# nrf7140_wificore register map
Vendor: Nordic Semiconductor; Series: nRF71; File version: 1
Registers are 32-bit, read-write, reset 0x0 unless marked. A register's access mark holds for its fields unless they carry their own. Offsets are from the block's base; [hi:lo] are bit positions; lines under a group give offsets from that group; {n}, {i} and the like mark numbered series; 'fields as' and 'values as' point back to an identical list; <NAME> marks a mode.

## RPUPHY (part 5 of 8) — WIFICore RPU PHY peripherals
Base 0x48080000; alternate view of RPUMAC
0xC000 WLAN_RTM_FD group — Unspecified
  0x00 RESET — WLAN RTM FD RESET
    [2] WLANRTMFDSTATSCOUNTERSRESET — Self-clearing software reset for the statistics counters.
    [1] WLANRTMFDLATCHEDSOFTWARERESET — Latched software reset.
    [0] WLANRTMFDPULSEDSOFTWARERESET — Self-clearing software reset.
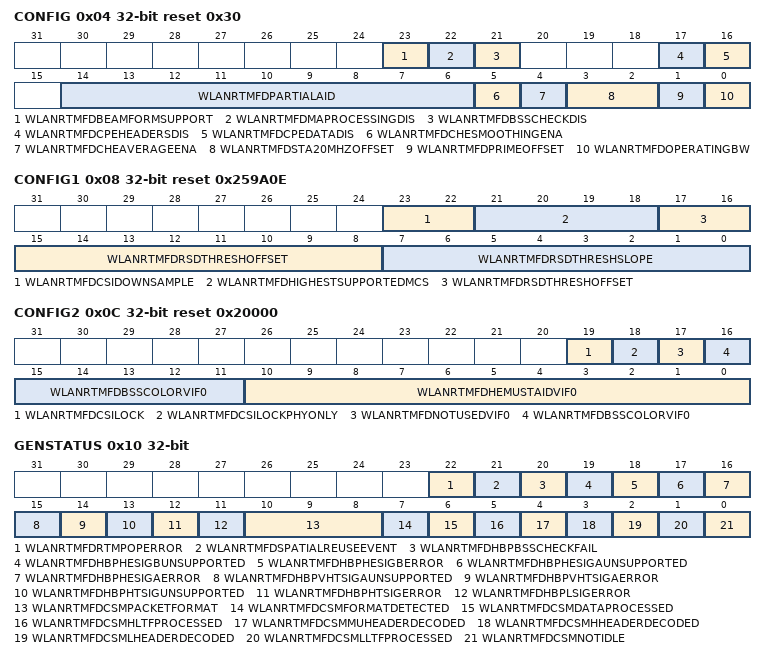
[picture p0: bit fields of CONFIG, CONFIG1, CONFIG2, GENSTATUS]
  0x04 CONFIG reset 0x30 — WLAN RTM FD CONFIG
    [23] WLANRTMFDBEAMFORMSUPPORT — Enable support for Beamforming. When disabled the unsupported flag will be rised when a NDP is detected.
    [22] WLANRTMFDMAPROCESSINGDIS — Disable midambles processing. When disabled the MIMO Channel Estimation matrix is not updated for the midambles.
    [21] WLANRTMFDBSSCHECKDIS — Disable BSS association checks: PARTIAL_AID and BSS_COLOR.
    [17] WLANRTMFDCPEHEADERSDIS — Disable CPE compensation for headers OFDM symbols.
    [16] WLANRTMFDCPEDATADIS — Disable CPE compensation for data OFDM symbols.
    [14:6] WLANRTMFDPARTIALAID — Partial association ID : combination of the association ID and the BSSID.
    [5] WLANRTMFDCHESMOOTHINGENA — Enable / disable channel estimation smoothing.
    [4] WLANRTMFDCHEAVERAGEENA — Enable / disable L-LTF and L-SIG channel estimations average. L-LTF estimation is output when the average is disabled.
    [3:2] WLANRTMFDSTA20MHZOFFSET — Selects the 20MHz partition of the BSS operating bandwidth (up to 80 MHz supported):0-1: when BSS operating bandwidth is 400-3: when BSS operating bandwidth is 80
    [1] WLANRTMFDPRIMEOFFSET — Prime offset for 40 MHz operating bandwidth:
      0=Low; 1=High
    [0] WLANRTMFDOPERATINGBW — Receiver operating bandwidth:
      0=20Mhz; 1=40Mhz
  0x08 CONFIG1 reset 0x259A0E — WLAN RTM FD CONFIG 1
    [23:22] WLANRTMFDCSIDOWNSAMPLE — CSI_DOWNSAMPLE:
      0=NoDownsample; 1=DownsampleBy2; 2=DownsampleBy4
    [21:18] WLANRTMFDHIGHESTSUPPORTEDMCS — Configure the highest supported MCS: detected packets with MCS greater than WLAN_RTM_FD_HIGHEST_SUPPORTED_MCS will be dropped.NOTE: the final highest MCS will be the minimum of this register and the internal value (i.e. HT: 7, VHT: 8 for SigBW20, 9 for SigBW40, HE-SU/MU: 9, HE-ER: 2 for SigBW20, 0 for SigBW40
    [17:8] WLANRTMFDRSDTHRESHOFFSET — Repeated L-SIG detector SNR threshold interpolation offset:threshold =WLAN_RTM_FD_RSD_THRESH_SLOPE * SNRdB + WLAN_RTM_FD_RSD_THRESH_OFFSET
    [7:0] WLANRTMFDRSDTHRESHSLOPE — Repeated L-SIG detector SNR threshold interpolation slope:threshold =WLAN_RTM_FD_RSD_THRESH_SLOPE * SNRdB + WLAN_RTM_FD_RSD_THRESH_OFFSET
  0x0C CONFIG2 reset 0x20000 — WLAN RTM FD CONFIG 2
    [19] WLANRTMFDCSILOCK — CSI lock value, use when WLAN_RTM_FD_CSI_LOCK_PHY_ONLY is set.
    [18] WLANRTMFDCSILOCKPHYONLY — Set when MAC is not present; WLAN_RTM_FD_CSI_LOCK is used.
    [17] WLANRTMFDNOTUSEDVIF0 — Set to mark the VIF0 as not used: STA-ID and BSS color will be ignored.
    [16:11] WLANRTMFDBSSCOLORVIF0 — VIF0 - BSS color of the BSS of which the STA is a member.
    [10:0] WLANRTMFDHEMUSTAIDVIF0 — VIF0 - STA identifier for HE-MU
  0x10 GENSTATUS ro — WLAN RTM FD GEN STATUS
    [22] WLANRTMFDRTMPOPERROR — Indicates POP error event in the RTM-FD.
    [21] WLANRTMFDSPATIALREUSEEVENT — Indicates Spatial Reuse is detected.
    [20] WLANRTMFDHBPBSSCHECKFAIL — Indicates BSS association check failure:- VHT : PARTIAL_AID not matching WLAN_RTM_FD_PARTIAL_AID- HE-SU/HE-ER : BSS_COLOR not matching WLAN_RTM_FD_BSS_COLOR- HE-MU : STA-ID not matching WLAN_RTM_FD_HEMU_STA_ID or not matchig broadcast STA-IDsNote: PARTIAL_AID and BSS_COLOR checks can be disabled by setting WLAN_RTM_FD_BSS_CHECK_DIS register to 1
    [19] WLANRTMFDHBPHESIGBUNSUPPORTED — Indicates HE-SIG-B unsupported feature:- MCS > 9- DCM = 1 if STBC = 1- NSTS > 0 if STBC = 0, NSTS > 1 if STBC = 1
    [18] WLANRTMFDHBPHESIGBERROR — Indicates HE-SIG-B decoding error (common and user fields):- invalid tail bits- CRC check failure
    [17] WLANRTMFDHBPHESIGAUNSUPPORTED — Indicates HE-SIG-A unsupported feature:[HE-SU/HE-ER]- UL detected (PPDU is addressed to an AP)- MCS > 9 if HE-SU, MCS > 2 if HE-ER and Bandwidth = 0, MCS > 0 if HE-ER and Bandwidth = 1- Bandwidth > 1- NSTS > 0 if STBC = 0, NSTS > 1 if STBC = 1- HE-TB detected[HE-MU]- HE-SIGB-MCS > 5, HE-SIGB-MCS = 2 or HE-SIGB-MC > 4 if HE-SIGB-DCM enabled- HE-LTF symbols > 8 if Doppler = 0, HE-LTF symbols > 4 if Doppler = 1
    [16] WLANRTMFDHBPHESIGAERROR — Indicates HE-SIG-A decoding error:- invalid reserved bits- invalid tail bits- CRC check failure- mod(L-SIG[length], 3) == 0
    [15] WLANRTMFDHBPVHTSIGAUNSUPPORTED — Indicates VHT-SIG-A unsupported feature:- Bandwidth > 1- Group ID not 0 or 63 (VHT-MU)- NSTS > 0 if STBC = 0, NSTS > 1 if STBC = 1- MCS > 8 if Bandwidth = 0, MCS > 9 if Bandwidth = 1
    [14] WLANRTMFDHBPVHTSIGAERROR — Indicates VHT-SIG-A decoding error:- invalid reserved bits- invalid tail bits- CRC check failure
    [13] WLANRTMFDHBPHTSIGUNSUPPORTED — Indicates HT-SIG unsupported feature:- MCS > 7- STBC > 1
    [12] WLANRTMFDHBPHTSIGERROR — Indicates HT-SIG decoding error:- invalid reserved bits- invalid tail bits- CRC check failure
    [11] WLANRTMFDHBPLSIGERROR — Indicates L-SIG decoding error:- invalid rate- invalid reserved bits- invalid tail bits- parity check failure
    [10:8] WLANRTMFDCSMPACKETFORMAT — Packet format:
      0=LLegacy; 1=Ht; 2=Reserve (This is reserved.); 3=Vht; 4=HeSu; 5=HeMu; 6=HeEr; 7=HeTb
    [7] WLANRTMFDCSMFORMATDETECTED — Indicates the packet format is detected (valid)
    [6] WLANRTMFDCSMDATAPROCESSED — Indicates all the data OFDM symbols are output to the RXP : L-DATA / HT-DATA / VHT-DATA / HE-DATA
    [5] WLANRTMFDCSMHLTFPROCESSED — Indicates the non-legacy LTF fields processing is completed : HT-LTF / VHT-LTF / HE-LTFestimated channel
    [4] WLANRTMFDCSMMUHEADERDECODED — Indicates the multi-user header is decoded (when it applies) : VHT-SIG-B / HE-SIG-B
    [3] WLANRTMFDCSMHHEADERDECODED — Indicates the non-legacy header is decoded (when it applies) : HT-SIG / VHT-SIG-A / HE-SIG-A
    [2] WLANRTMFDCSMLHEADERDECODED — Indicates the legacy header is decoded : L-SIG
    [1] WLANRTMFDCSMLLTFPROCESSED — Indicates the legacy LTF fields processing is completed : L-LTF estimated channel
    [0] WLANRTMFDCSMNOTIDLE — Indicates the training mode - frequency domain is not idle (i.e. processing packet)
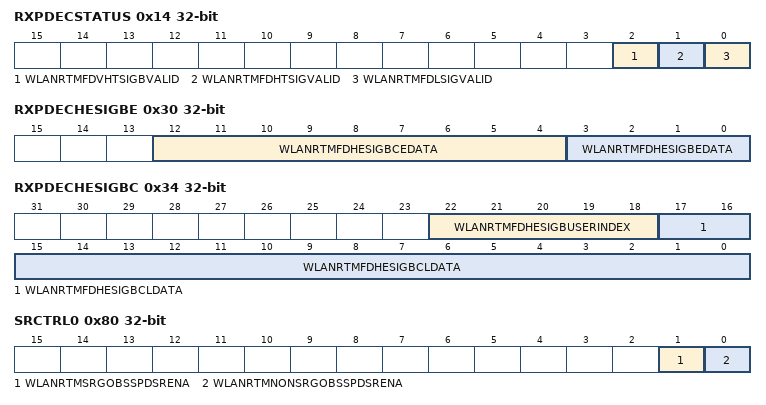
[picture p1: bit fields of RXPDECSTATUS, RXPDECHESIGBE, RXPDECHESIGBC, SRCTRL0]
  0x14 RXPDECSTATUS — WLAN RTM FD RXPDEC STATUS
    [2] WLANRTMFDVHTSIGBVALID — Indicates when the VHT-SIG-B decoded data is available.Note: this register is cleared when soft-reset
    [1] WLANRTMFDHTSIGVALID — Indicates when the HT-SIG / VHT-SIG_A / HE-SIG-A decoded data is available.Note: this register is cleared when soft-reset
    [0] WLANRTMFDLSIGVALID — Indicates when the L-SIG decoded data is available.Note: this register is cleared when soft-reset
  0x18 RXPDECLSIG — WLAN RTM FD RXPDEC LSIG
    [23:0] WLANRTMFDLSIGDATA — L-SIG decoded data - bits 23 .. 0
  0x1C RXPDECHTSIGL — WLAN RTM FD RXPDEC HTSIG L
    [23:0] WLANRTMFDHTSIGLDATA — HT-SIG / VHT-SIG-A / HE-SIG-A1 decoded data - bits 23 .. 0
  0x20 RXPDECHTSIGH — WLAN RTM FD RXPDEC HTSIG H
    [23:0] WLANRTMFDHTSIGHDATA — HT-SIG / VHT-SIG-A / HE-SIG-A decoded data - bits 47 .. 24
  0x24 RXPDECHESIGAE — WLAN RTM FD RXPDEC HESIGA E
    [3:0] WLANRTMFDHESIGAEDATA — HE-SIG-A decoded data - bits 51 .. 48
  0x28 RXPDECVHTSIGBL — WLAN RTM FD RXPDEC VHTSIGB L
    [23:0] WLANRTMFDVHTSIGBLDATA — VHT-SIG-B / HE-SIG-B decoded data - bits 23 .. 0
  0x2C RXPDECVHTSIGBH — WLAN RTM FD RXPDEC VHTSIGB H
    [23:0] WLANRTMFDVHTSIGBHDATA — VHT-SIG-B / HE-SIG-B decoded data - bits 47 .. 24
  0x30 RXPDECHESIGBE — WLAN RTM FD RXPDEC HESIGB E
    [12:4] WLANRTMFDHESIGBCEDATA — HE-SIG-B common field data - bits 26 .. 18
    [3:0] WLANRTMFDHESIGBEDATA — HE-SIG-B decoded data - bits 51 .. 48
  0x34 RXPDECHESIGBC — WLAN RTM FD RXPDEC HESIGB C
    [22:18] WLANRTMFDHESIGBUSERINDEX — HE-SIG-B user field index
    [17:0] WLANRTMFDHESIGBCLDATA — HE-SIG-B common field data - bits 17 .. 0
  0x38 STATSCOUNTER0 — WLAN RTM FD STATS COUNTER 0
    [23:0] WLANRTMOFDMCORRELATIONPASSCOUNT — Number of detected OFDM packets.
  0x3C STATSCOUNTER1 — WLAN RTM FD STATS COUNTER 1
    [23:0] WLANRTMLTFCORRELATIONFAILCOUNT — Number of OFDM packets failed FSB detection - peak not found or peak below the threshold.
  0x40 STATSCOUNTER2 — WLAN RTM FD STATS COUNTER 2
    [23:0] WLANRTMLSIGDECODEFAILCOUNT — Number of OFDM packets failed L-SIG checks - parity or other conditions.
  0x44 STATSCOUNTER3 — WLAN RTM FD STATS COUNTER 3
    [23:0] WLANRTMHTSIGDECODEFAILCOUNT — Number of OFDM packets failed HT-SIG checks - CRC or other conditions.
  0x48 STATSCOUNTER4 — WLAN RTM FD STATS COUNTER 4
    [23:0] WLANRTMVHTSIGADECODEFAILCOUNT — Number of OFDM packets failed VHT-SIG-A checks - CRC or other conditions.
  0x4C STATSCOUNTER5 — WLAN RTM FD STATS COUNTER 5
    [23:0] WLANRTMHESIGADECODEFAILCOUNT — Number of OFDM packets failed HE-SIG-A checks - CRC or other conditions.
  0x50 STATSCOUNTER6 — WLAN RTM FD STATS COUNTER 6
    [23:0] WLANRTMHESIGBDECODEFAILCOUNT — Number of OFDM packets failed HE-SIG-B checks - CRC or other conditions.
  0x54 FRAMECOUNTER0 — WLAN RTM FD FRAME COUNTER 0
    [23:0] WLANRTMLEGACYFRAMECOUNT — Number of Legacy frames received - increments when the last DATA symbol is sent to the RXP.
  0x58 FRAMECOUNTER1 — WLAN RTM FD FRAME COUNTER 1
    [23:0] WLANRTMHTFRAMECOUNT — Number of HT frames received - increments when the last DATA symbol is sent to the RXP.
  0x5C FRAMECOUNTER2 — WLAN RTM FD FRAME COUNTER 2
    [23:0] WLANRTMVHTFRAMECOUNT — Number of VHT frames received - increments when the last DATA symbol is sent to the RXP.
  0x60 FRAMECOUNTER3 — WLAN RTM FD FRAME COUNTER 3
    [23:0] WLANRTMHESUFRAMECOUNT — Number of HE-SU frames received - increments when the last DATA symbol is sent to the RXP.
  0x64 FRAMECOUNTER4 — WLAN RTM FD FRAME COUNTER 4
    [23:0] WLANRTMHEERFRAMECOUNT — Number of HE-ER-SU frames received - increments when the last DATA symbol is sent to the RXP.
  0x68 FRAMECOUNTER5 — WLAN RTM FD FRAME COUNTER 5
    [23:0] WLANRTMHEMUFRAMECOUNT — Number of HE-MU frames received - increments when the last DATA symbol is sent to the RXP.
  0x6C FRAMECOUNTER6 — WLAN RTM FD FRAME COUNTER 6
    [23:0] WLANRTMUNSUPPORTEDFRAMECOUNT — Number of received OFDM packets with unsupporterd features - increments when fields of HT-SIG / VHT-SIG-A /HE-SIG-A / HE-SIG-B indicate capabilities/features that are not supported by STA and header is succesfully decoded.
  0x70 FRAMECOUNTER7 — WLAN RTM FD FRAME COUNTER 7
    [23:0] WLANRTMOTHERSTAFRAMECOUNT — Number of received OFDM packets where packet ID not matcing the STA ID - increments when Partial AID (VHT), BSS Color (HE-SU/HE-ER-SU) or User Field (HE-MU) not matching the configured value and header is succesfully decoded.
  0x74 FRAMECOUNTER8 — WLAN RTM FD FRAME COUNTER 8
    [23:0] WLANRTMVHTNDPFRAMECOUNT — Number of VHT NDP frames received - increments when the last VHT-LTF symbol is sent to the SVD.
  0x78 FRAMECOUNTER9 — WLAN RTM FD FRAME COUNTER 9
    [23:0] WLANRTMHESUNDPFRAMECOUNT — Number of HE-SU NDP frames received - increments when the last HE-LTF symbol is sent to the SVD.
  0x7C STATSCOUNTER7 — WLAN RTM FD STATS COUNTER 7
    [23:0] WLANRTMS2LTIMEOUTFAILCOUNT — Number of OFDM packets failed due to missing S2L event.
  0x80 SRCTRL0 — WLAN RTM FD SR CTRL 0
    [1] WLANRTMSRGOBSSPDSRENA — Enable spatial reuse in overlapping-BSS with preamble detection in spatial reuse group cases.
    [0] WLANRTMNONSRGOBSSPDSRENA — Enable spatial reuse in overlapping-BSS with preamble detection in non-spatial reuse group cases.
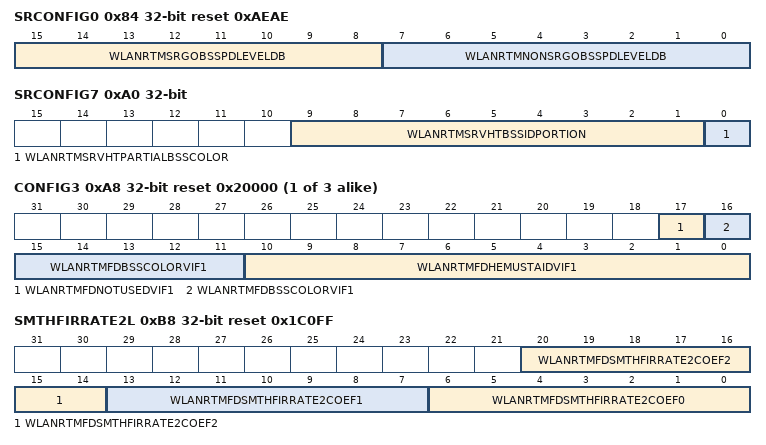
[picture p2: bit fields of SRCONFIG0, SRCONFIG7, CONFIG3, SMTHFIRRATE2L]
  0x84 SRCONFIG0 reset 0xAEAE — WLAN RTM FD SR CONFIG 0
    [15:8] WLANRTMSRGOBSSPDLEVELDB — Preamble detection level in dBm for spatial reuse group cases (s7.0). Valid Range : -82 to -62 dBm
    [7:0] WLANRTMNONSRGOBSSPDLEVELDB — Preamble detection level in dBm for non spatial reuse group cases (s7.0). Valid Range : -82 to -62 dBm
  0x88 SRCONFIG1 — WLAN RTM FD SR CONFIG 1
    [23:0] WLANRTMSRGPARTIALBSSIDBITMAP0 — Indicates the Partial BSSID values used by members of the SRG of which the transmitting STA is a member - bits 23 downto 0. Note: Each bit of the bitmap corresponds to one of the 64 possible values of BSSID[39:44], where the lowest numbered bit corresponds to Partial BSSID value 0 and the highest numbered bit corresponds to Partial BSSID value 63
  0x8C SRCONFIG2 — WLAN RTM FD SR CONFIG 2
    [23:0] WLANRTMSRGPARTIALBSSIDBITMAP1 — Indicates the Partial BSSID values used by members of the SRG of which the transmitting STA is a member - bits 47 downto 24. Note: Each bit of the bitmap corresponds to one of the 64 possible values of BSSID[39:44], where the lowest numbered bit corresponds to Partial BSSID value 0 and the highest numbered bit corresponds to Partial BSSID value 63
  0x90 SRCONFIG3 — WLAN RTM FD SR CONFIG 3
    [15:0] WLANRTMSRGPARTIALBSSIDBITMAP2 — Indicates the Partial BSSID values used by members of the SRG of which the transmitting STA is a member - bits 63 downto 48. Note: Each bit of the bitmap corresponds to one of the 64 possible values of BSSID[39:44], where the lowest numbered bit corresponds to Partial BSSID value 0 and the highest numbered bit corresponds to Partial BSSID value 63
  0x94 SRCONFIG4 — WLAN RTM FD SR CONFIG 4
    [23:0] WLANRTMSRGBSSCOLORBITMAP0 — Indicates the BSS color values used by members of the SRG of which the transmitting STA is a member - bits 23 downto 0. Note: Each bit of the bitmap corresponds to one of the 64 BSS colors, where the lowest numbered bit corresponds to BSS color value 0 and the highest numbered bit corresponds to BSS color value 63.The bit in the bitmap that corresponds to the BSS color value 0 is reserved
  0x98 SRCONFIG5 — WLAN RTM FD SR CONFIG 5
    [23:0] WLANRTMSRGBSSCOLORBITMAP1 — Indicates the BSS color values used by members of the SRG of which the transmitting STA is a member - bits 47 downto 24. Note: Each bit of the bitmap corresponds to one of the 64 BSS colors, where the lowest numbered bit corresponds to BSS color value 0 and the highest numbered bit corresponds to BSS color value 63.The bit in the bitmap that corresponds to the BSS color value 0 is reserved
  0x9C SRCONFIG6 — WLAN RTM FD SR CONFIG 6
    [15:0] WLANRTMSRGBSSCOLORBITMAP2 — Indicates the BSS color values used by members of the SRG of which the transmitting STA is a member - bits 63 downto 48. Note: Each bit of the bitmap corresponds to one of the 64 BSS colors, where the lowest numbered bit corresponds to BSS color value 0 and the highest numbered bit corresponds to BSS color value 63.The bit in the bitmap that corresponds to the BSS color value 0 is reserved
  0xA0 SRCONFIG7 — WLAN RTM FD SR CONFIG 7
    [9:1] WLANRTMSRVHTBSSIDPORTION — VHT specific BSSID portion
    [0] WLANRTMSRVHTPARTIALBSSCOLOR — Partial BSS color field/
  0xA4 STATSCOUNTER8 — WLAN RTM FD STATS COUNTER 8
    [23:0] WLANRTMSPATIALREUSEEVENTCOUNT — Number of Spatial Reuse events detected.
  {0x9C+4j} CONFIG{j} reset 0x20000 (j=3..5) — WLAN RTM FD CONFIG {j}
    [17] WLANRTMFDNOTUSEDVIF{j-2} — Set to mark the VIF{j-2} as not used: STA-ID and BSS color will be ignored.
    [16:11] WLANRTMFDBSSCOLORVIF{j-2} — VIF{j-2} - BSS color of the BSS of which the STA is a member.
    [10:0] WLANRTMFDHEMUSTAIDVIF{j-2} — VIF{j-2} - STA identifier for HE-MU
  0xB4 CONFIG6 — WLAN RTM FD CONFIG 6
    [10:0] WLANRTMFDHEMUBSSIDINDEX — BSSID index field for a non-transmitted BSSID; set to 0 for transmitted BSSID
  0xB8 SMTHFIRRATE2L reset 0x1C0FF — WLAN RTM FD SMTH FIR RATE2 L
    [20:14] WLANRTMFDSMTHFIRRATE2COEF2 — Smoothing FIR filter, Tu/GI rate 2, coefficient 2, s0.6, default 7
    [13:7] WLANRTMFDSMTHFIRRATE2COEF1 — Smoothing FIR filter, Tu/GI rate 2, coefficient 1, s0.6, default 1
    [6:0] WLANRTMFDSMTHFIRRATE2COEF0 — Smoothing FIR filter, Tu/GI rate 2, coefficient 0, s0.6, default -1
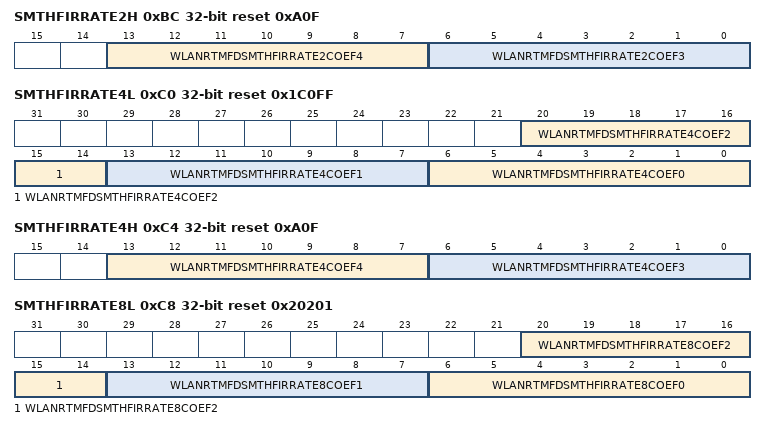
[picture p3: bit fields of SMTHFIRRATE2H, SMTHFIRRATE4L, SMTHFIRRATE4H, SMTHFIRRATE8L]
  0xBC SMTHFIRRATE2H reset 0xA0F — WLAN RTM FD SMTH FIR RATE2 H
    [13:7] WLANRTMFDSMTHFIRRATE2COEF4 — Smoothing FIR filter, Tu/GI rate 2, coefficient 4, s0.6, default 20
    [6:0] WLANRTMFDSMTHFIRRATE2COEF3 — Smoothing FIR filter, Tu/GI rate 2, coefficient 3, s0.6, default 15
  0xC0 SMTHFIRRATE4L reset 0x1C0FF — WLAN RTM FD SMTH FIR RATE4 L
    [20:14] WLANRTMFDSMTHFIRRATE4COEF2 — Smoothing FIR filter, Tu/GI rate 4, coefficient 2, s0.6, default 7
    [13:7] WLANRTMFDSMTHFIRRATE4COEF1 — Smoothing FIR filter, Tu/GI rate 4, coefficient 1, s0.6, default 1
    [6:0] WLANRTMFDSMTHFIRRATE4COEF0 — Smoothing FIR filter, Tu/GI rate 4, coefficient 0, s0.6, default -1
  0xC4 SMTHFIRRATE4H reset 0xA0F — WLAN RTM FD SMTH FIR RATE4 H
    [13:7] WLANRTMFDSMTHFIRRATE4COEF4 — Smoothing FIR filter, Tu/GI rate 4, coefficient 4, s0.6, default 20
    [6:0] WLANRTMFDSMTHFIRRATE4COEF3 — Smoothing FIR filter, Tu/GI rate 4, coefficient 3, s0.6, default 15
  0xC8 SMTHFIRRATE8L reset 0x20201 — WLAN RTM FD SMTH FIR RATE8 L
    [20:14] WLANRTMFDSMTHFIRRATE8COEF2 — Smoothing FIR filter, Tu/GI rate 8, coefficient 2, s0.6, default 8
    [13:7] WLANRTMFDSMTHFIRRATE8COEF1 — Smoothing FIR filter, Tu/GI rate 8, coefficient 1, s0.6, default 4
    [6:0] WLANRTMFDSMTHFIRRATE8COEF0 — Smoothing FIR filter, Tu/GI rate 8, coefficient 0, s0.6, default 1
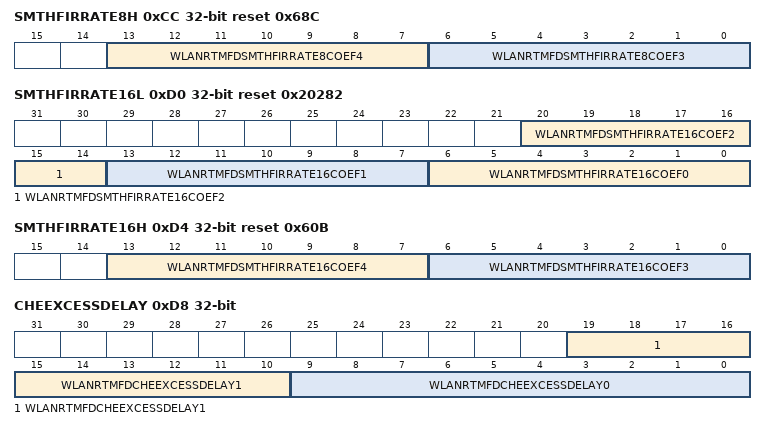
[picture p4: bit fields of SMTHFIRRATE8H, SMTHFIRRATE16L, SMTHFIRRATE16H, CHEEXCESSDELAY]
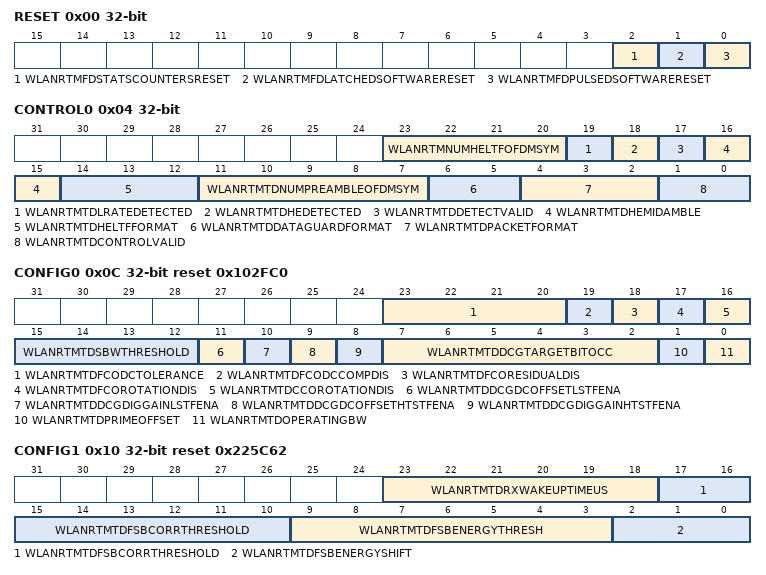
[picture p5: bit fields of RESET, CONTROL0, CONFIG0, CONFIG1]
  0xCC SMTHFIRRATE8H reset 0x68C — WLAN RTM FD SMTH FIR RATE8 H
    [13:7] WLANRTMFDSMTHFIRRATE8COEF4 — Smoothing FIR filter, Tu/GI rate 8, coefficient 4, s0.6, default 13
    [6:0] WLANRTMFDSMTHFIRRATE8COEF3 — Smoothing FIR filter, Tu/GI rate 8, coefficient 3, s0.6, default 12
  0xD0 SMTHFIRRATE16L reset 0x20282 — WLAN RTM FD SMTH FIR RATE16 L
    [20:14] WLANRTMFDSMTHFIRRATE16COEF2 — Smoothing FIR filter, Tu/GI rate 16, coefficient 2, s0.6, default 8
    [13:7] WLANRTMFDSMTHFIRRATE16COEF1 — Smoothing FIR filter, Tu/GI rate 16, coefficient 1, s0.6, default 5
    [6:0] WLANRTMFDSMTHFIRRATE16COEF0 — Smoothing FIR filter, Tu/GI rate 16, coefficient 0, s0.6, default 2
  0xD4 SMTHFIRRATE16H reset 0x60B — WLAN RTM FD SMTH FIR RATE16 H
    [13:7] WLANRTMFDSMTHFIRRATE16COEF4 — Smoothing FIR filter, Tu/GI rate 16, coefficient 4, s0.6, default 12
    [6:0] WLANRTMFDSMTHFIRRATE16COEF3 — Smoothing FIR filter, Tu/GI rate 16, coefficient 3, s0.6, default 11
  0xD8 CHEEXCESSDELAY ro — WLAN RTM FD CHE EXCESS DELAY
    [19:10] WLANRTMFDCHEEXCESSDELAY1 — Excess Delay estimate at channel smoothing for the second stream, s0.9
    [9:0] WLANRTMFDCHEEXCESSDELAY0 — Excess Delay estimate at channel smoothing for the first stream, s0.9
  0xDC CHEDMALENGTH — WLAN RTM FD CHE DMA LENGTH
    [8:0] WLANRTMFDCHEDMALENGTH — Transfer specified number of channel estimates to the EDC through the channel estimates TBus read port. Register value decrements as the channel estimates are transferred.
0xD000 WLAN_RTM_TD group — Unspecified
  0x00 RESET — WLAN RTM TD RESET
    [2] WLANRTMTDSTATSCOUNTERSRESET — Self-clearing software reset for the statistics counters.
    [1] WLANRTMTDLATCHEDSOFTWARERESET — Latched software reset.
    [0] WLANRTMTDPULSEDSOFTWARERESET — Self-clearing software reset.
  0x04 CONTROL0 — WLAN RTM TD CONTROL 0
    [23:20] WLANRTMNUMHELTFOFDMSYM — Number of HE-LTF OFDM symbols in the preamble section (do NOT include the midables HE-LTFs)Note: default value set when software reset
    [19] WLANRTMTDLRATEDETECTED — L-SIG 6 Mbps detection flag :Note: default value set when software reset
      0=LSigRateNot6Mbps; 1=LSigRateIs6Mbps
    [18] WLANRTMTDHEDETECTED — HE detection flag :Note: default value set when software reset
      0=NonHeDetected; 1=HeDetected
    [17] WLANRTMTDDETECTVALID — Indicates the detection control register fields are valid.Note: default value set when software reset
      0=Detection control register fields not yet set; 1=WLAN_RTM_TD_HE_DETECTED and WLAN_RTM_TD_LRATE_DETECTED are valid
    [16:15] WLANRTMTDHEMIDAMBLE — HE-LTF format :Note: default value set when software reset
      0=NoMidambles; 1=Reserve (This is reserved.); 2=Midambles every 10 OFDM data symbols,; 3=Midambles every 20 OFDM data symbols
    [14:12] WLANRTMTDHELTFFORMAT — HE-LTF format :0: 1x HE-LTF (3.2us)+ 0.8us GI,1: 1x HE-LTF (3.2us)+ 1.6us GI,2: 2x HE-LTF (6.4us)+ 0.8us GI,3: 2x HE-LTF (6.4us)+ 1.6us GI,4: 4x HE-LTF (12.8us) + 0.8us GI,5: 4x HE-LTF (12.8us) + 3.2us GI,6-7: ReservedNote: default value set when software reset
    [11:7] WLANRTMTDNUMPREAMBLEOFDMSYM — Number of preamble / header OFDM symbols, counting after L-SIG (i.e. for legacy packet the value is zero)Note: default value set when software reset
    [6:5] WLANRTMTDDATAGUARDFORMAT — Guard duration for DATA symbols :
      0=04UsLegacyShort; 1=08UsLegacyLong; 2=16Us; 3=32Us
    [4:2] WLANRTMTDPACKETFORMAT — Packet format:Note: default value set when software reset
      values as WLAN_RTM_FD.GENSTATUS.WLANRTMFDCSMPACKETFORMAT
    [1:0] WLANRTMTDCONTROLVALID — Indicates the control registers WLAN_RTM_TD_CONTROL_0 and WLAN_RTM_TD_CONTROL_1 are valid.Note: default value set when software reset
      0=Control registers not yet set; 1=Only WLAN_RTM_TD_PACKET_FORMAT is valid; 2=Legacy fields decoding control registers are valid; 3=All the control registers are valid
  0x08 CONTROL1 — WLAN RTM TD CONTROL 1
    [23:0] WLANRTMTDNUMDATAOFDMSYM — Number of data and midamble (HE only) OFDM symbols. Considered valid if WLAN_RTM_TD_CONTROL_VALID is 2 or 3.Note: default value set when software reset
  0x0C CONFIG0 reset 0x102FC0 — WLAN RTM TD CONFIG 0
    [23:20] WLANRTMTDFCODCTOLERANCE — ?? Tolerance for the FCO-DC estimation calculation (u-8.12).
    [19] WLANRTMTDFCODCCOMPDIS — Disable / enable fine DC offset compensation in FCO.
    [18] WLANRTMTDFCORESIDUALDIS — Disable / enable residual frequency offset correction.
    [17] WLANRTMTDFCOROTATIONDIS — Disable / enable fine carrier frequency offset correction.
    [16] WLANRTMTDCCOROTATIONDIS — Disable / enable coarse carrier frequency offset correction.
    [15:12] WLANRTMTDSBWTHRESHOLD — Signal bandwidth detection threshold (u4.0).
    [11] WLANRTMTDDCGDCOFFSETLSTFENA — Enable / disable DC offset compensation for L-STF.
    [10] WLANRTMTDDCGDIGGAINLSTFENA — Enable / disable digital gain compensation for L-STF.
    [9] WLANRTMTDDCGDCOFFSETHTSTFENA — Enable / disable DC offset compensation for HT-STF/VHT-STF/HE-STF (2nd AGC enabled).
    [8] WLANRTMTDDCGDIGGAINHTSTFENA — Enable / disable digital gain compensation for HT-STF/VHT-STF/HE-STF (2nd AGC enabled).
    [7:2] WLANRTMTDDCGTARGETBITOCC — Digital gain target bit occupancy in dB (u6.0).Default value corresponds to 12 bits SCP (full scale) and 18 dB headroom.
    [1] WLANRTMTDPRIMEOFFSET — Prime offset for 40 MHz operating bandwidth:
      0=Low; 1=High
    [0] WLANRTMTDOPERATINGBW — Receiver operating bandwidth:
      0=20Mhz; 1=40Mhz
  0x10 CONFIG1 reset 0x225C62 — WLAN RTM TD CONFIG 1
    [23:18] WLANRTMTDRXWAKEUPTIMEUS — Standby to Active time in us (u4.2).Note: Used to enable RX prior to expiry of the packet duration counter when Power Save mode is active.
    [17:10] WLANRTMTDFSBCORRTHRESHOLD — Fine symbol boundary energy correlation threshold ratio (u0.8).
    [9:3] WLANRTMTDFSBENERGYTHRESH — Fine symbol boundary peak detection threshold ratio (u0.7).
    [2:0] WLANRTMTDFSBENERGYSHIFT — Fine symbol boundary energy scale shift (u3.0).
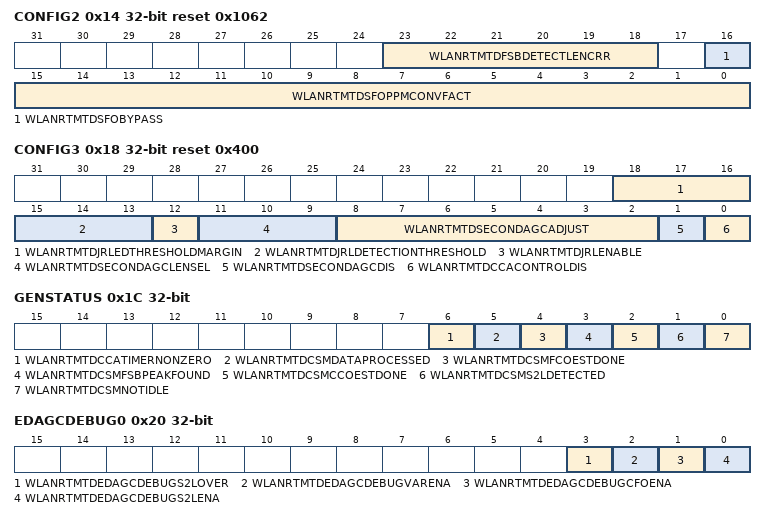
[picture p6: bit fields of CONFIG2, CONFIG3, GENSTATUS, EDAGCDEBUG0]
  0x14 CONFIG2 reset 0x1062 — WLAN RTM TD CONFIG 2
    [23:18] WLANRTMTDFSBDETECTLENCRR — Fine symbol boundary detection length correction factor (s5.0).
    [16] WLANRTMTDSFOBYPASS — Bypass Sample Frequency Offset when set to 1
    [15:0] WLANRTMTDSFOPPMCONVFACT — Sampling Frequency Offset, time tracking conversion factor: value of [resampler factor] * OpBW/fc,where OpBw is the operating bandwidth and fc is the channel centre frequency. (u-4.20)Note: default value set for resampler factor = 1, OpBW = 20MHz and fc = 5GHz
  0x18 CONFIG3 reset 0x400 — WLAN RTM TD CONFIG 3
    [18:16] WLANRTMTDJRLEDTHRESHOLDMARGIN — Headroom added to the minimum variance for OFDM correlation once Jammer signal is detected in dB (u3.0).
    [15:13] WLANRTMTDJRLDETECTIONTHRESHOLD — Jammer Detection Threshold. Total number of s2lFails required to trigger Jammer detection - 1 (u3.0).
    [12] WLANRTMTDJRLENABLE — Enable/disable Jammer Rejection Logic : ED threshold and minimum variance for OFDM correlation PASS increased toED RSSI snapshot + EdThresholdMargin when Jammer is detected.
    [11:9] WLANRTMTDSECONDAGCLENSEL — Second AGC estimation window length selection: ceil(log2(0.8*Fs)) - 3, where Fs is the ADC sampling rate.Note: default value is set assuming Fs equals 40MHz
    [8:2] WLANRTMTDSECONDAGCADJUST — Second AGC start wait time adjustment in number of samples. (s6.0)
    [1] WLANRTMTDSECONDAGCDIS — Disable / enable AGC control for the second estimation (ED/AGC).
    [0] WLANRTMTDCCACONTROLDIS — Disable / enable CCA control for correlation indication and status known (ED).Timer non-zero flag always zero when disabled.
  0x1C GENSTATUS ro — WLAN RTM TD GEN STATUS
    [6] WLANRTMTDCCATIMERNONZERO — CCA timer non-zero
    [5] WLANRTMTDCSMDATAPROCESSED — Indicates all the OFDM symbols are output to the FFT
    [4] WLANRTMTDCSMFCOESTDONE — Indicates the fine frequency offset is estimated
    [3] WLANRTMTDCSMFSBPEAKFOUND — Indicates the FSB index is calculated : LTF correlation
    [2] WLANRTMTDCSMCCOESTDONE — Indicates the coarse frequency offset is estimated
    [1] WLANRTMTDCSMS2LDETECTED — Indicates the S2L event is asserted by the ED
    [0] WLANRTMTDCSMNOTIDLE — Indicates the training mode - time domain is not idle (i.e. processing packet)
  0x20 EDAGCDEBUG0 — WLAN RTM TD EDAGC DEBUG 0
    [3] WLANRTMTDEDAGCDEBUGS2LOVER — S2LOver flag emulation : overwrites input signal cin_s2l_over_event.
    [2] WLANRTMTDEDAGCDEBUGVARENA — Enable/disable ED-AGC debug support : ED-AGC prime variance signals from registers WLAN_RTM_TD_EDAGC_PRIME20_VAR/WLAN_RTM_TD_EDAGC_PRIME40_VAR.
    [1] WLANRTMTDEDAGCDEBUGCFOENA — Enable/disable ED-AGC debug support : ED-AGC CFO signals from registers WLAN_RTM_TD_EDAGC_CFO_RE/WLAN_RTM_TD_EDAGC_CFO_IM.
    [0] WLANRTMTDEDAGCDEBUGS2LENA — Enable/disable ED-AGC debug support : ED-AGC S2L-over signal from register WLAN_RTM_TD_EDAGC_DEBUG_S2LOVER.
  0x24 EDAGCDEBUG1 — WLAN RTM TD EDAGC DEBUG 1
    [23:0] WLANRTMTDEDAGCCFORE — ED CFO emulation : overwrites input signal cin_edagccfo_re (s0.23).
  0x28 EDAGCDEBUG2 — WLAN RTM TD EDAGC DEBUG 2
    [23:0] WLANRTMTDEDAGCCFOIM — ED CFO emulation : overwrites input signal cin_edagccfo_im (s0.23).
  0x2C EDAGCDEBUG3 — WLAN RTM TD EDAGC DEBUG 3
    [19:0] WLANRTMTDEDAGCPRIME20VAR — ED Prime20 variance emulation : overwrites input signal cin_edprime20_var (u20.0).
  0x30 EDAGCDEBUG4 — WLAN RTM TD EDAGC DEBUG 4
    [19:0] WLANRTMTDEDAGCPRIME40VAR — ED Prime20 variance emulation : overwrites input signal cin_edprime40_var (u20.0).
  0x34 DCGSTATUS0 ro — WLAN RTM TD DCG STATUS 0
    [23:0] WLANRTMTDDCGDCOFFSETLSTF — DC offset estimation for L-STF - complex (s-1.12).
  0x38 DCGSTATUS1 ro — WLAN RTM TD DCG STATUS 1
    [8:0] WLANRTMTDDCGDIGITALGAINLSTFDB — Digital gain estimation for L-STF in dBs (s6.2).
  0x3C DCGSTATUS2 ro — WLAN RTM TD DCG STATUS 2
    [23:0] WLANRTMTDDCGDCOFFSETHTSTF — DC offset estimation for HT-STF/VHT-STF/HE-STF - complex (s-1.12).
  0x40 DCGSTATUS3 ro — WLAN RTM TD DCG STATUS 3
    [8:0] WLANRTMTDDCGDIGITALGAINHTSTFDB — Digital gain estimation for HT-STF/VHT-STF/HE-STF in dBs (s6.2).
  0x44 CFOSTATUS0 ro — WLAN RTM TD CFO STATUS 0
    [15:0] WLANRTMTDCCOFREQUENCYOFFSET — Coarse frequency offset estimation (s-5.20).
  0x48 CFOSTATUS1 ro — WLAN RTM TD CFO STATUS 1
    [15:0] WLANRTMTDFCOFREQUENCYOFFSET — Fine frequency offset estimation (s-5.20).
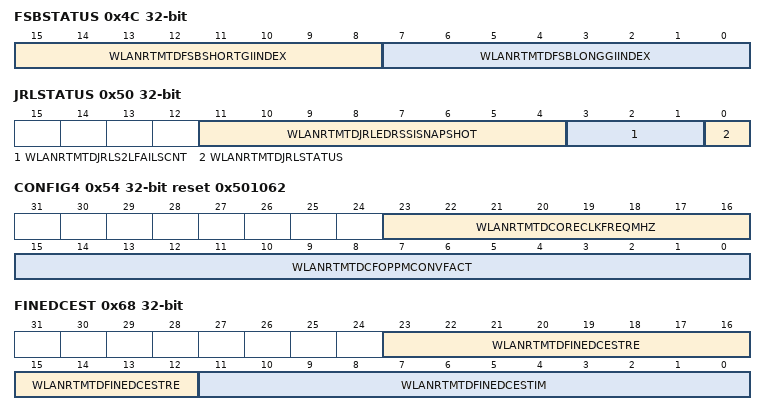
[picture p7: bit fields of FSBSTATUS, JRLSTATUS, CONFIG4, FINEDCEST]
  0x4C FSBSTATUS ro — WLAN RTM TD FSB STATUS
    [15:8] WLANRTMTDFSBSHORTGIINDEX — FSB index for the short guard interval (s7.0).
    [7:0] WLANRTMTDFSBLONGGIINDEX — FSB index for the long guard interval (s7.0).
  0x50 JRLSTATUS ro — WLAN RTM TD JRL STATUS
    [11:4] WLANRTMTDJRLEDRSSISNAPSHOT — ED RSSI (in dBm) snapshot taken after the latest ED-done event.
    [3:1] WLANRTMTDJRLS2LFAILSCNT — Consecutive number of S2L fails after every ED.
    [0] WLANRTMTDJRLSTATUS — Jammer detection status (cleared on low energy detection):
      0=no Jammer has been detected; 1=Jammer has been detected (number of consecutive S2L fails equals JRL_DETECTION_THRESHOLD)
  0x54 CONFIG4 reset 0x501062 — WLAN RTM TD CONFIG 4
    [23:16] WLANRTMTDCORECLKFREQMHZ — Core clock frequency in MHz. (u8.0)
    [15:0] WLANRTMTDCFOPPMCONVFACT — Carrier Frequency Offset, to PPM conversion factor: value of OpBW/fc,where OpBw is the operating bandwidth and fc is the channel centre frequency. (u-4.20)Note: default value set for OpBW = 20MHz and fc = 5GHz
  0x58 STATSCOUNTER0 — WLAN RTM TD STATS COUNTER 0
    [23:0] WLANRTMLOWENERGYEVENTCOUNT — Number of low energy events detected.
  0x5C STATSCOUNTER1 — WLAN RTM TD STATS COUNTER 1
    [23:0] WLANRTMPOPEVENTCOUNT — Number of packet-over-packet events detected.
  0x60 CONFIG5 reset 0x1D — WLAN RTM TD CONFIG 5
    [7:0] WLANRTMRSSICONVFACTOR — The LTF-RSSI conversion factor. s7.0This factor represents the conversion from voltage domain (power in dBm) in analog to digital representation of IQ's.LTF_RSSI_DBM = LTF_POWER_DB - AGC_GAIN_DB - DGC_GAIN_DB - WLAN_RTM_RSSI_CONV_FACTOR
  0x64 RSSISTATUS ro — WLAN RTM TD RSSI STATUS
    [7:0] WLANRTMTDRSSILTFDBM — The RSSI computation of HT-LTF/VHT-LTF/HE-LTF is an indicative of the DATA field power in dBm.
  0x68 FINEDCEST ro — WLAN RTM TD FINE DC EST
    [23:12] WLANRTMTDFINEDCESTRE — Fine DC estimation real part S-1.12.
    [11:0] WLANRTMTDFINEDCESTIM — Fine DC estimation imaginary part S-1.12.
  0x6C STATSCOUNTER2 — WLAN RTM TD STATS COUNTER 2
    [23:0] WLANRTMMIDPACKETDETECTCOUNT — Number of mid-packet detected.
  0x70 DEBUGGING — WLAN RTM TD DEBUG
    [1:0] WLANRTMTDDEBUG — Enable debug registers WLAN_RTM_TD_DEBUG_VALID and WLAN_RTM_TD_DEBUG_ENABLE
      0=Disabled; 1=ValidEnable; 2=Sticky(Valid), Sticky(Enable); 3=Valid & Enable, Sticky(Valid & Enable)
  0x74 DEBUGVALID ro — WLAN RTM TD DEBUG VALID
    [19:0] WLANRTMTDDEBUGVALID — Live state of the valid flow control signals0: valid_up_l1: valid_dw_l2: dcg_valid_up3: dcg_fco_valid_up4: dcg_valid_dw5: atn_valid_up6: atn_valid_dw7: cco_valid_up8: cco_valid_dw9: cco_atn_valid10: atn_cco_valid11: fsb_valid_up12: fsb_valid_dw13: fco_valid_up14: fco_valid_dw15: fco_atn_valid16: atn_fco_valid17: rsd_atn_valid18: sbw_valid_up19: sbw_valid_dw
  0x78 DEBUGENABLE ro — WLAN RTM TD DEBUG ENABLE
    [19:0] WLANRTMTDDEBUGENABLE — Live state of the enable flow control signals0: enable_up_l1: enable_dw_l2: dcg_enable_up3: dcg_fco_enable_up4: dcg_enable_dw5: atn_enable_up6: atn_enable_dw7: cco_enable_up8: cco_enable_dw9: cco_atn_enable10: atn_cco_enable11: fsb_enable_up12: fsb_enable_dw13: fco_enable_up14: fco_enable_dw15: fco_atn_enable16: atn_fco_enable17: rsd_atn_enable18: sbw_enable_up19: sbw_enable_dw
  0x7C CONTROL2 — WLAN RTM TD CONTROL 2
    [1:0] WLANRTMTDSCOCCUPANCYLEVEL — Sub-carriers occupancy level:0: High : >= 81.25 percent of sub-carriers in a OFDM symbol are used1: Mid: >= 20.3125 percent of sub-carriers in a OFDM symbol are used2: Low: <20.3125 percent of sub-carriersin a OFDM symbolare usedConsidered valid if WLAN_RTM_TD_CONTROL_VALID is 3.Note: default value set when software reset
0xF000 WLAN_FFT group — Unspecified
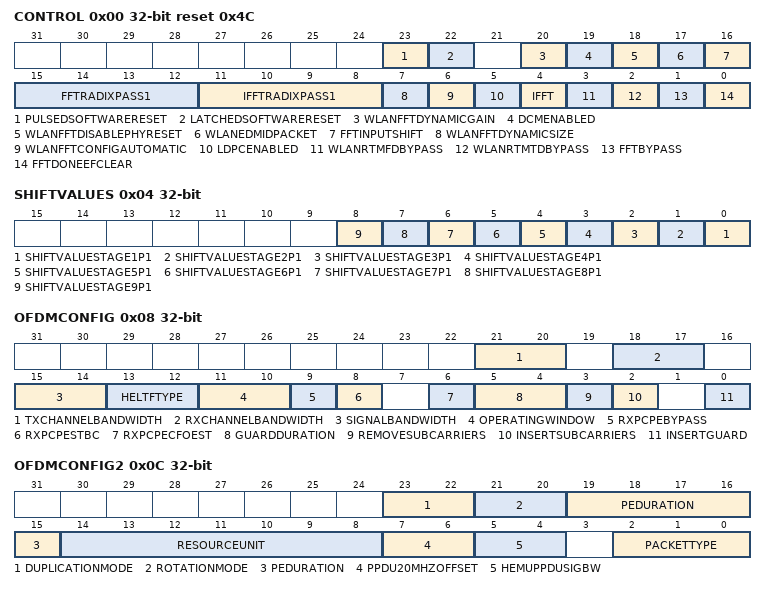
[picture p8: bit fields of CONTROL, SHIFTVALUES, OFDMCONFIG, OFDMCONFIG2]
  0x00 CONTROL reset 0x4C — WLAN FFT CONTROL
    [23] PULSEDSOFTWARERESET — 0 : Do nothing1 : Apply a pulsed software resetThis bit is automatically returns to 0
    [22] LATCHEDSOFTWARERESET
      0=RemoveReset; 1=ApplyReset
    [20] WLANFFTDYNAMICGAIN — Dynamic FFT gain (stages shift values):
      0=FFT gain configured by the WLAN_FFT_SHIFT_VALUES registers; 1=FFT gain configured by sideband signal
    [19] DCMENABLED
      0=DCM decoding is disabled; 1=DcmDecodingIsEnabled
    [18] WLANFFTDISABLEPHYRESET — Disable automatic PHY reset.
      0=PHY will automatically reset; 1=PHY will not automatically reset
    [17] WLANEDMIDPACKET — Mid-packet energy detection flag:
      0=DSSS or OFDM packet detected; 1=MidPacketDetected
    [16] FFTINPUTSHIFT — 0 : No data shift at the input of the FFT engine.Input to FFT engine is in [0..N-1] order, where N is size of FFT.1 : Data at the input of the FFT engine is shifted such that thesecond half of input vector is swapped with the first half.Input to FFT engine is in [N/2..N-1,0,..N/2-1] order.
    [15:12] FFTRADIXPASS1 — Select the radix used on the first FFT pass.Options are0-5 : reserved6 : radix=647 : radix=1288 : radix=2569 : radix=51210-15 : reserved
    [11:8] IFFTRADIXPASS1 — Select the radix used on the first IFFT pass.Options are0-5 : reserved6 : radix=647 : radix=1288 : radix=2569 : radix=51210-15 : reserved
    [7] WLANFFTDYNAMICSIZE — Dynamic FFT size enable.
      0=FFT size configured by the FFT_RADIX_PASS1/IFFT_RADIX_PASS1 registers; 1=FFT size configured by sideband signal
    [6] WLANFFTCONFIGAUTOMATIC — Enable automatic configuration of the WLAN_FFT.
      0=Manual configuration mode; 1=Automatic configuration mode
    [5] LDPCENABLED
      0=LDPC decoding is disabled; 1=LDPC decoding is enabled
    [4] IFFT
      0=PerformFftOperation; 1=PerformIfftOperation
    [3] WLANRTMFDBYPASS — Set the Receiver Training Mode - Frequency Domain in bypass:Note: The RTM-FD is set in bypass when FFT_BYPASS is 1.
      0=Do not bypass Rx Training Mode Time Domain; 1=Bypass Rx Training Mode Time Domain
    [2] WLANRTMTDBYPASS — Set the Receiver Training Mode - Time Domain in bypass:
      values as WLANRTMFDBYPASS
    [1] FFTBYPASS
      0=Perform FFT/IFFT operation; 1=Bypass
    [0] FFTDONEEFCLEAR — 0 : Do nothing1 : Clear the event flag WLAN_FFT_DONE_EF_STATUSThis bit automatically returns to 0
  0x04 SHIFTVALUES — WLAN FFT SHIFT VALUES
    [n-1] SHIFTVALUESTAGE{n}P1 (n=1..9) — SHIFT SELECT for Pass 1 / Stage {n}.Options are as above
  0x08 OFDMCONFIG — WLAN FFT OFDM CONFIG
    [21:20] TXCHANNELBANDWIDTH — Selects the channel bandwidth
      0=20Mhz; 1=40Mhz; 2=80Mhz; 3=Reserve (This is reserved.)
    [18:17] RXCHANNELBANDWIDTH — Selects the channel bandwidth
      0=20Mhz; 1=40Mhz; 2=80Mhz; 3=Reserve (This is reserved.)
    [15:14] SIGNALBANDWIDTH — Selects the signal bandwidth0 : 20MHz1 : 40MHz2 : 80MHz3 : reservedMust be equal or less than CHANNEL_BANDWIDTH.For receive, see the OPERATING_WINDOW description.For transmit, when signal bandwidth is less than channel bandwidth, input OFDM symbol will be duplicatedbefore performing inverse FFT. If channel bandwidth is two times signal bandwidth then OFDM symbol will beduplicated and if channel bandwidth is four times signal bandwidth then OFDM symbol will be quadrupled.
    [13:12] HELTFTYPE — Type of HE-LTF preamble. For HE formats only.
      0=1XHeLtf; 1=2XHeLtf; 2=4XHeLtf
    [11:10] OPERATINGWINDOW — For receive selects the operating window when the channel bandwidth is not equal to the signal bandwidth0 : -3 Most lower operating window1 : -1 Lower operating window2 : +1 Upper operating window3 : +3 Most upper operating windowWhen the channel bandwidth is 40MHz and the signal bandwidth is 20MHz, the operating window should be configured toeither value 1 (lower operating window) or 2 (upper operating window). When the channel bandwidth is 80MHz and the signalbandwidth is 20MHz, the operating window should be configured to either value 1, 2, 3, or 4. 80MHz cbw/ 40MHz sbwshould follow the first case.
    [9] RXPCPEBYPASS — CPE compensation control.0 : CPE compensation1 : BypassThis field is used when REMOVE_SUB_CARRIERS is active (RX mode).In both cases pilots will be discarded but when bypass is not activeCPE compensation will be performed.
    [8] RXPCPESTBC — Selects STBC mode. HT-packets only.
      0=NonStbc; 1=Stbc
    [6] RXPCPECFOEST — When set enables the CFO estimation based on the CPE.
    [5:4] GUARDDURATION — Specifies the guard duration to be inserted or removed:
      0=04Us; 1=08Us; 2=16Us; 3=32Us
    [3] REMOVESUBCARRIERS — 0: Do nothing1: For receive, remove the null sub-carriers from the FFT output data stream.Pilots will be outputted first following by data sub-carriers.
    [2] INSERTSUBCARRIERS
      0=DoNothing; 1=For transmit, insert null sub-carriers into the FFT input data stream
    [0] INSERTGUARD
      0=DoNothing; 1=For transmit, insert Guard to the FFT output data stream
  0x0C OFDMCONFIG2 — WLAN FFT OFDM CONFIG 2
    [23:22] DUPLICATIONMODE
      0=NoDuplication; 1=OFDM symbol duplicated prior to IFFT; 2=OFDM symbol quadrupled prior to IFFT
    [21:20] ROTATIONMODE
      0=NoRotation; 1=Rotation by gamma factor for 40MHz signal bandwidth; 2=RotationByGammaFacto2 (Rotation by gamma factor for 80MHz signal bandwidth)
    [19:15] PEDURATION — Duration of Packet Extension in microseconds. Only applicable for HE packets.
    [14:8] RESOURCEUNIT — Used to determine the positions of pilot and null sub-carriers.Valid range of values for SIGNAL_BANDWIDTH = 20 MHz are [0-8, 37-40, 53-54, 61].Valid range of values for SIGNAL_BANDWIDTH = 40 MHz are [0-17, 37-44, 53-56, 61-62, 65].Only applicable for HE packets.(SIGNAL_BANDWIDTH in WLAN_FFT_OFDM_CONFIG register)
    [7:6] PPDU20MHZOFFSET — Selects the 20MHz partition of the PPDU bandwidth (up to 80 MHz supported):0-1: when BSS operating bandwidth is 40 MHz0-3: when BSS operating bandwidth is 80 MHzNOTE: only used when HE-MU packet and HEMU_PPDU_SIGBW >= 40 MHz
    [5:4] HEMUPPDUSIGBW — Operating BW of the BSS (Basic Service Set):NOTE: only used for HE-MU packets
      0=20Mhz; 1=40Mhz; 2=80Mhz; 3=Reserve (This is reserved.)
    [2:0] PACKETTYPE — Selects packet type:0 : Legacy1 : HT-MF2 : HT-GF3 : VHT4 : HE-SU5 : HE-MU6 : HE-ER7 : HE-TBPackets 0-3 (Legacy, HT_MF, HT_GF, VHT) are in Pre-HE group with OFDM symbol length of 3.2us.HE packet has 12.8us OFDM symbol length.NOTE: Whenever packet_type is configured the initial state of scrambler will be set accordingly.Scrambler is used within CPE block to generate PN sequence for pilot sign generation. PN sequencehas 127 elements and cyclically repeats after 127 OFDM symbols.
  {0x10+4j} RXPCPECHSTREAM1PILOT[{j}] (j=0..7) — Description collection: WLAN FFT RXP CPE CH STREAM1 PILOT
    [23:0] RXPCPECHSTREAM1PILOT — Channel estimate for stream 1 on the pilot subcarrier.
  {0x30+4j} RXPCPECHSTREAM2PILOT[{j}] (j=0..7) — Description collection: WLAN FFT RXP CPE CH STREAM2 PILOT
    [23:0] RXPCPECHSTREAM2PILOT — Channel estimate for stream 2 on the pilot subcarrier.
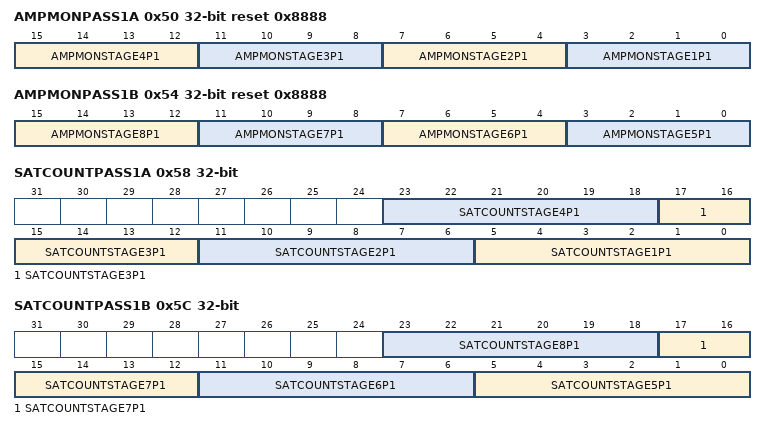
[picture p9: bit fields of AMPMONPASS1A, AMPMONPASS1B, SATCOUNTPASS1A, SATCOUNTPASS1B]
  0x50 AMPMONPASS1A ro reset 0x8888 — WLAN FFT AMP MON PASS1A
    [15:12] AMPMONSTAGE4P1 — Amplitude Monitor - Pass 1 Stage 415 : full_scale14 : 3 dB below full scale13 : 6 dB below full scale..8 : 21 dB below full scale0-7 : reserved
    [11:8] AMPMONSTAGE3P1 — Amplitude Monitor - Pass 1 Stage 3 : format as above
    [7:4] AMPMONSTAGE2P1 — Amplitude Monitor - Pass 1 Stage 2 : format as above
    [3:0] AMPMONSTAGE1P1 — Amplitude Monitor - Pass 1 Stage 1 : format as above
  0x54 AMPMONPASS1B ro reset 0x8888 — WLAN FFT AMP MON PASS1B
    [15:12] AMPMONSTAGE8P1 — Amplitude Monitor - Pass 1 Stage 815 : full_scale14 : 3 dB below full scale13 : 6 dB below full scale..8 : 21 dB below full scale0-7 : reserved
    [11:8] AMPMONSTAGE7P1 — Amplitude Monitor - Pass 1 Stage 7 : format as above
    [7:4] AMPMONSTAGE6P1 — Amplitude Monitor - Pass 1 Stage 6 : format as above
    [3:0] AMPMONSTAGE5P1 — Amplitude Monitor - Pass 1 Stage 5 : format as above
  0x58 SATCOUNTPASS1A ro — WLAN FFT SAT COUNT PASS1A
    [6n-1:6n-6] SATCOUNTSTAGE{n}P1 (n=1..4) — Number of saturations in pass1 stage {n}
  0x5C SATCOUNTPASS1B ro — WLAN FFT SAT COUNT PASS1B
    [6n-25:6n-30] SATCOUNTSTAGE{n}P1 (n=5..8) — Number of saturations in pass1 stage {n}
  0x60 STATUS ro — WLAN FFT STATUS
    [0] FFTDONEEFSTATUS — FFT_DONE_EF_STATUS is set to 1 when an FFT operation completes,and is cleared when 1 is written to FFT_DONE_EF_CLEAR in the WLAN_FFT_CONTROL register.
  0x64 FINALSHIFTVALUE — WLAN FFT FINAL SHIFT VALUE
    [4:0] FINALSHIFTVALUE — Signed 2's compliment shift value to be applied after the final stage of an FFT.
  0x68 MAXRADIX ro reset 0x100 — WLAN FFT MAX RADIX
    [10:0] MAXRADIX — MAX RADIX for FFT Engine
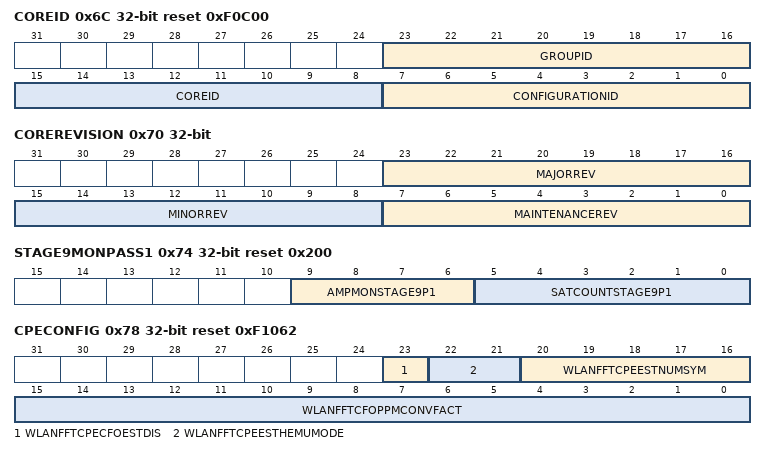
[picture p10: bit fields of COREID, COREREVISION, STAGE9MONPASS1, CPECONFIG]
  0x6C COREID ro reset 0xF0C00 — WLAN FFT CORE ID
    [23:16] GROUPID — Identifies core as part of an IMG IP family group. [0x0F = UCC]
    [15:8] COREID — Identifies the member of the IP group. [0x0C = FFT]
    [7:0] CONFIGURATIONID — Configuration of the core.
  0x70 COREREVISION ro — WLAN FFT CORE REVISION
    [23:16] MAJORREV — Family Major Release Revision.
    [15:8] MINORREV — Core Minor Release Revision.
    [7:0] MAINTENANCEREV — Maintenance Release Revision.
  0x74 STAGE9MONPASS1 ro reset 0x200 — WLAN FFT STAGE9 MON PASS1
    [9:6] AMPMONSTAGE9P1 — Amplitude Monitor - Pass 1 Stage 9
    [5:0] SATCOUNTSTAGE9P1 — Number of saturations in pass1 stage 9
  0x78 CPECONFIG reset 0xF1062 — WLAN FFT CPE CONFIG
    [23] WLANFFTCPECFOESTDIS — Disable the CFO estimation based on the CPE : ignore RXP_CPE_CFO_EST field
    [22:21] WLANFFTCPEESTHEMUMODE — CPE based frequency offset estimation mode for HE-MU packets:
      0=Use HE-SIG-B and Data symbols CPE estimations (final HE-SIG-B in ppm is sum to the Data ppm estimations); 1=Use HE-SIG-B symbols CPE estimations only; 2=Use Data symbols CPE estimations only (if there is only one data Symbol then the HE-SIG-B is used)
    [20:16] WLANFFTCPEESTNUMSYM — Number of CPE estimations used for the CPE based frequency offset estimation.
    [15:0] WLANFFTCFOPPMCONVFACT — Carrier Frequency Offset, to PPM conversion factor: value of OpBW/fc,where OpBw is the operating bandwidth and fc is the channel centre frequency. (u-4.20)Note: default value set for OpBW = 20MHz and fc = 5GHz
  0x7C CPESTATUS ro — WLAN FFT CPE STATUS
    [15:0] WLANFFTCPEFREQUENCYOFFSET — CPE based frequency offset estimation (s-5.20).
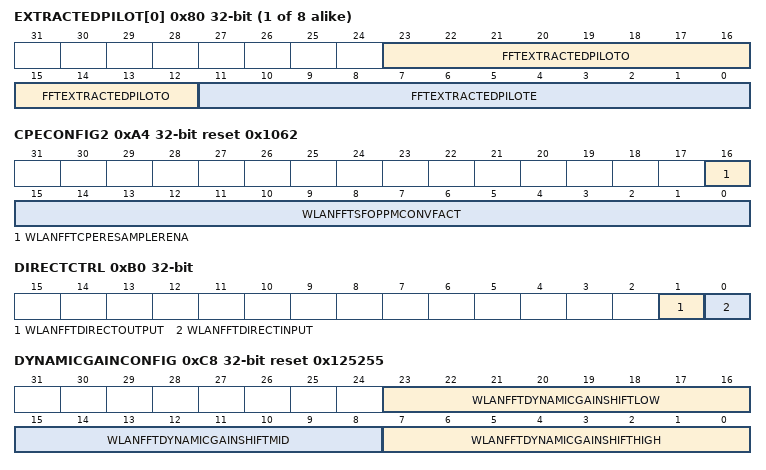
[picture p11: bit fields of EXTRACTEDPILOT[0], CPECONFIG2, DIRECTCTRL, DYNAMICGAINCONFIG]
  {0x80+4j} EXTRACTEDPILOT[{j}] (j=0..7) ro — Description collection: WLAN FFT EXTRACTED PILOT
    [23:12] FFTEXTRACTEDPILOTO — FFT_EXTRACTED_PILOT_O is updated on every odd pilot extracted from FFT output stream.The 6 MSBs of the real and imaginary part are stored.
    [11:0] FFTEXTRACTEDPILOTE — FFT_EXTRACTED_PILOT_E is updated on every even pilot extracted from FFT output stream.The 6 MSBs of the real and imaginary part are stored.
  0xA0 MCSCONFIG — WLAN FFT MCS CONFIG
    [23:20] MCSVALUE — Modulation and coding scheme
  0xA4 CPECONFIG2 reset 0x1062 — WLAN FFT CPE CONFIG 2
    [16] WLANFFTCPERESAMPLERENA — Enable CPE estimation based SFO error update to the SCP resampler.
    [15:0] WLANFFTSFOPPMCONVFACT — Sampling Frequency Offset, time tracking conversion factor: value of [resampler factor] * OpBW/fc,where OpBw is the operating bandwidth and fc is the channel centre frequency. (u-4.20)Note: default value set for resampler factor = 1, OpBW = 20MHz and fc = 5GHz
  0xA8 CPECONFIG3 — WLAN FFT CPE CONFIG 3
    [3:0] WLANRXPCPEFIELD — Selects packet type:0: LSIG (L)1: LDATA (L)2: HTSIG (L)3: HTDATA (HT)4: VHTSIGA (L)5: VHTSIGB (HT)6: VHTDATA (VHT)7: RLSIG (L)8: HESIGA_SU (HT)9: HESIGA_X (HT)10 : HESIGA_ER (HT)11 : HESIGA_MU (HT)12 : HESIGB (VHT)13 : HEDATA_SU (HE)14 : HEDATA_ER (HE)15 : HEDATA_MU (HE)Packet types 0-3 (Legacy, HT_MF, HT_GF, VHT) are in Pre-HE group with OFDM symbol length of 3.2us.HE packet has 12.8us OFDM symbol length.NOTE: Whenever field is configured the initial state of scrambler will be set accordingly.Scrambler is used within CPE block to generate PN sequence for pilot sign generation. PN sequencehas 127 elements and cyclically repeats after 127 OFDM symbols.
  0xAC TBUSRDMODE — WLAN FFT TBUS RD MODE
    [1] WLANFFTTBUSRDDISCARD — Discard PBus debug mode output (WLAN_FFT_TBUS_RD_MODE=1):
      0=Output to PBus (debug mode); 1=DiscardOutput
  0xB0 DIRECTCTRL — WLAN FFT DIRECT CTRL
    [1] WLANFFTDIRECTOUTPUT — Selects whether TXP output goes to next pipeline stage or EDC (tbus).
      0=Tbus; 1=Direct
    [0] WLANFFTDIRECTINPUT — Selects whether TXP input comes from previous pipeline stage or EDC (tbus).
      0=Tbus; 1=Direct
  0xB4 STARTINGSTSNUM — WLAN FFT STARTING STS NUM
    [1:0] STARTINGSTSNUM — Starting STS num for cyclic shift delay
      0=0; 1=2X; 2=1X; 3=3X
  0xB8 TBUSRDSIGNATURE ro reset 0xFFFFFF — WLAN FFT TBUS RD SIGNATURE
    [23:0] WLANFFTTBUSRDSIGNATURE — TBus debug output data signature.
  0xBC DEBUGGING — WLAN FFT DEBUG
    [1:0] WLANFFTDEBUG — Enable debug registers WLAN_FFT_DEBUG_VALID and WLAN_FFT_DEBUG_ENABLE
      values as WLAN_RTM_TD.DEBUGGING.WLANRTMTDDEBUG
  0xC0 DEBUGVALID ro — WLAN FFT DEBUG VALID
    [17:0] WLANFFTDEBUGVALID — Live state of the valid flow control signals0: FFT WR1: Unused - Tied to 02: Unused - Tied to 03: Null SC Insertion Input4: Null SC Insertion Output5: FFT Input FIFO Input6: FFT Input FIFO Output7: Engine Input8: Engine Output9: RTM FFT Input10: RTM FFT Output11: FFT Output FIFO Input12: FFT Output FIFO Output13: Raw FFT Output14: Unused - Tied to 015: Unused - Tied to 016: Unused - Tied to 017: FFT RD
  0xC4 DEBUGENABLE ro — WLAN FFT DEBUG ENABLE
    [17:0] WLANFFTDEBUGENABLE — Live state of the enable flow control signals0: FFT WR1: Unused - Tied to 02: Unused - Tied to 03: Null SC Insertion Input4: Null SC Insertion Output5: FFT Input FIFO Input6: FFT Input FIFO Output7: Engine Input8: Engine Output9: RTM FFT Input10: RTM FFT Output11: FFT Output FIFO Input12: FFT Output FIFO Output13: Raw FFT Output14: Unused - Tied to 015: Unused - Tied to 016: Unused - Tied to 017: FFT RD
  0xC8 DYNAMICGAINCONFIG reset 0x125255 — WLAN FFT DYNAMIC GAIN CONFIG
    [23:16] WLANFFTDYNAMICGAINSHIFTLOW — FFT gain configuration (shift values) when WLAN_FFT_DYNAMIC_GAIN is set and SC occupancy is Low
    [15:8] WLANFFTDYNAMICGAINSHIFTMID — FFT gain configuration (shift values) when WLAN_FFT_DYNAMIC_GAIN is set and SC occupancy is Mid
    [7:0] WLANFFTDYNAMICGAINSHIFTHIGH — FFT gain configuration (shift values) when WLAN_FFT_DYNAMIC_GAIN is set and SC occupancy is High
  0xCC IGNOREWRSYNC — WLAN FFT IGNORE WR SYNC
    [0] WLANFFTIGNOREWRSYNC
